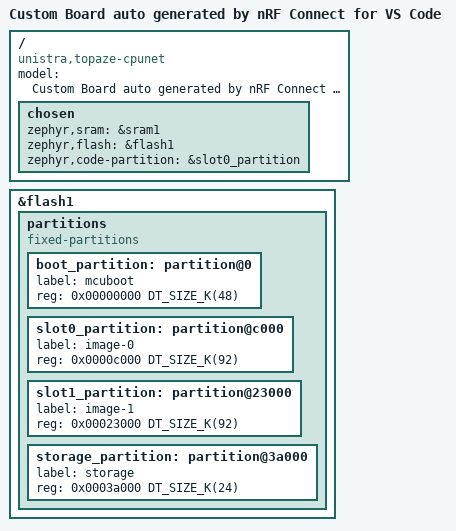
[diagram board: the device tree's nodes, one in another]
/* ============================================================
 * This file is the base DTS for the topaze board for the NETWORK CPU
 * 
 * It only serve the purpose of including required files,
 * do not place any modifications here or they will need to be
 * multiple times.
 *
 * l.heywang
 * 18/02/2025
 *
 * ============================================================
 */

/dts-v1/;
#include <nordic/nrf5340_cpunet_qkaa.dtsi>
#include "DTSI/topaze-pinctrl.dtsi"
#include "DTSI/topaze-aliases.dtsi"

/ {
	model = "Custom Board auto generated by nRF Connect for VS Code";
	compatible = "unistra,topaze-cpunet";

	chosen {
		zephyr,sram = &sram1;
		zephyr,flash = &flash1;
		zephyr,code-partition = &slot0_partition;
	};
};

&flash1 {
	partitions {
		compatible = "fixed-partitions";
		#address-cells = <1>;
		#size-cells = <1>;

		boot_partition: partition@0 {
			label = "mcuboot";
			reg = <0x00000000 DT_SIZE_K(48)>;
		};

		slot0_partition: partition@c000 {
			label = "image-0";
			reg = <0x0000c000 DT_SIZE_K(92)>;
		};

		slot1_partition: partition@23000 {
			label = "image-1";
			reg = <0x00023000 DT_SIZE_K(92)>;
		};

		storage_partition: partition@3a000 {
			label = "storage";
			reg = <0x0003a000 DT_SIZE_K(24)>;
		};
	};
};

#include "topaze-shared_sram.dtsi"
